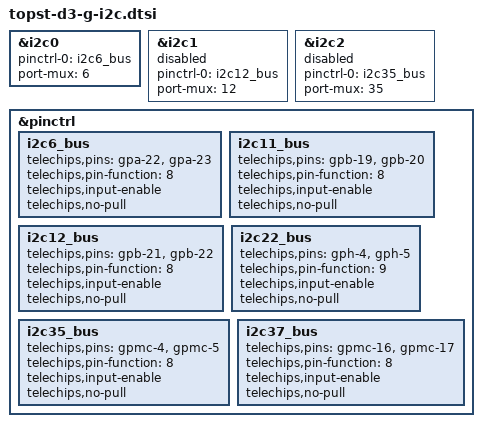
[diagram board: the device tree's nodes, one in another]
// SPDX-License-Identifier: (GPL-2.0-or-later OR MIT)
/*
 * Copyright (C) 2023 Telechips Inc.
 */

/* PMIC */
&i2c0 {
	pinctrl-names = "default";
	pinctrl-0 = <&i2c6_bus>;
	port-mux = <6>;
	status = "okay";
};

/* MIPI 0 */
&i2c1 {
	pinctrl-names = "default";
	pinctrl-0 = <&i2c12_bus>;
	port-mux = <12>;
	status = "disabled";
};

/* MIPI 1 */
&i2c2 {
	pinctrl-names = "default";
	pinctrl-0 = <&i2c35_bus>;
	port-mux = <35>;
	status = "disabled";
};

&pinctrl {
	/omit-if-no-ref/
	i2c6_bus: i2c6_bus {
		telechips,pins = "gpa-22", "gpa-23";
		telechips,pin-function = <8>;
		telechips,input-enable;
		telechips,no-pull;
	};

	/omit-if-no-ref/
	i2c11_bus: i2c11_bus {
		telechips,pins = "gpb-19", "gpb-20";
		telechips,pin-function = <8>;
		telechips,input-enable;
		telechips,no-pull;
	};

	/omit-if-no-ref/
	i2c12_bus: i2c12_bus {
		telechips,pins = "gpb-21", "gpb-22";
		telechips,pin-function = <8>;
		telechips,input-enable;
		telechips,no-pull;
	};

	/omit-if-no-ref/
	i2c22_bus: i2c22_bus {
		telechips,pins = "gph-4", "gph-5";
		telechips,pin-function = <9>;
		telechips,input-enable;
		telechips,no-pull;
	};

	/omit-if-no-ref/
	i2c35_bus: i2c35_bus {
		telechips,pins = "gpmc-4", "gpmc-5";
		telechips,pin-function = <8>;
		telechips,input-enable;
		telechips,no-pull;
	};

	/omit-if-no-ref/
	i2c37_bus: i2c37_bus {
		telechips,pins = "gpmc-16", "gpmc-17";
		telechips,pin-function = <8>;
		telechips,input-enable;
		telechips,no-pull;
	};

};
